VERSION ""

NS_ :

BS_:

BU_: AMS

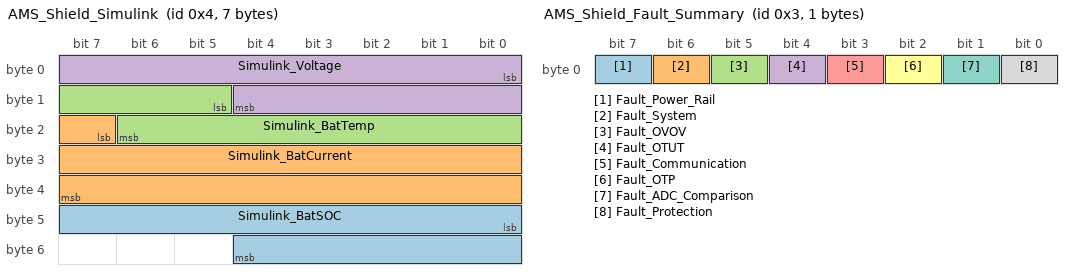
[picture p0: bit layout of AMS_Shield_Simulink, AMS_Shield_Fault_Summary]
BO_ 4 AMS_Shield_Simulink: 7 AMS
 SG_ Simulink_BatSOC : 40|13@1+ (0.001,0) [0|8.191] "V" Vector__XXX
 SG_ Simulink_BatCurrent : 23|17@1+ (0.001,0) [0|131.071] "A" Vector__XXX
 SG_ Simulink_BatTemp : 13|10@1+ (0.1,0) [0|102.3] "°C" Vector__XXX
 SG_ Simulink_Voltage : 0|13@1+ (0.001,0) [0|8.191] "V" Vector__XXX

BO_ 3 AMS_Shield_Fault_Summary: 1 AMS
 SG_ Fault_Power_Rail : 7|1@1+ (1,0) [0|1] "" Vector__XXX
 SG_ Fault_System : 6|1@1+ (1,0) [0|1] "" Vector__XXX
 SG_ Fault_OVOV : 5|1@1+ (1,0) [0|1] "" Vector__XXX
 SG_ Fault_OTUT : 4|1@1+ (1,0) [0|1] "" Vector__XXX
 SG_ Fault_Communication : 3|1@1+ (1,0) [0|1] "" Vector__XXX
 SG_ Fault_OTP : 2|1@1+ (1,0) [0|1] "" Vector__XXX
 SG_ Fault_ADC_Comparison : 1|1@1+ (1,0) [0|1] "" Vector__XXX
 SG_ Fault_Protection : 0|1@1+ (1,0) [0|1] "" Vector__XXX

BO_ 2 AMS_Shield_CellVoltages: 7 AMS
 SG_ Voltage_Cell2 : 40|13@1+ (0.001,0) [0|8.191] "V" Vector__XXX
 SG_ Voltage_Cell1 : 24|13@1+ (0.001,0) [0|8.191] "V" Vector__XXX

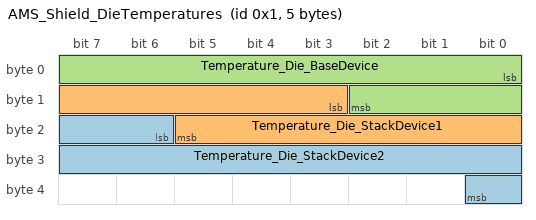
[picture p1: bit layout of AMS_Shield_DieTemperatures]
BO_ 1 AMS_Shield_DieTemperatures: 5 AMS
 SG_ Temperature_Die_StackDevice2 : 22|11@1+ (0.1,0) [0|204.7] "°C" Vector__XXX
 SG_ Temperature_Die_StackDevice1 : 11|11@1+ (0.1,0) [0|204.7] "°C" Vector__XXX
 SG_ Temperature_Die_BaseDevice : 0|11@1+ (0.1,0) [0|204.7] "°C" Vector__XXX

BO_ 0 AMS_Shield_CellTemperatures: 3 AMS
 SG_ Temperature_Cell2 : 10|10@1+ (0.1,0) [0|102.3] "°C" Vector__XXX
 SG_ Temperature_Cell1 : 0|10@1+ (0.1,0) [0|102.3] "°C" Vector__XXX

BA_DEF_  "BusType" STRING ;
BA_DEF_ SG_  "GenSigSendType" ENUM  "Cyclic","OnWrite","OnWriteWithRepetition","OnChange","OnChangeWithRepetition","IfActive","IfActiveWithRepetition","NoSigSendType";
BA_DEF_ BO_  "GenMsgSendType" ENUM  "Cyclic","not_used","not_used","not_used","not_used","Cyclic","not_used","IfActive","NoMsgSendType";
BA_DEF_ BO_  "GenMsgCycleTime" INT 0 0;
BA_DEF_DEF_  "BusType" "";
BA_DEF_DEF_  "GenSigSendType" "Cyclic";
BA_DEF_DEF_  "GenMsgSendType" "NoMsgSendType";
BA_DEF_DEF_  "GenMsgCycleTime" 0;
BA_ "GenMsgCycleTime" BO_ 4 50;
BA_ "GenMsgCycleTime" BO_ 3 50;
BA_ "GenMsgCycleTime" BO_ 2 50;
BA_ "GenMsgCycleTime" BO_ 1 50;
BA_ "GenMsgCycleTime" BO_ 0 50;
